# CY8C5888LTI_LP097 register map
File version: 0.1
Registers are 8-bit, read-write, no defined reset value unless marked. A register's access mark holds for its fields unless they carry their own. Offsets are from the block's base; [hi:lo] are bit positions; 'fields as' and 'values as' point back to an identical list.

## MOTOR_ON_OFF_2
Base 0x00000000
0x40006576 MOTOR_ON_OFF_2_CONTROL_REG

## MY_TIMER_REG
Base 0x00000000
0x4000647A MY_TIMER_REG_CONTROL_REG

## MOTOR_DRIVER_TYPE
Base 0x00000000
0x40006472 MOTOR_DRIVER_TYPE_CONTROL_REG

## PACER_RESET
Base 0x00000000
0x40006579 PACER_RESET_CONTROL_REG

## ADC_SOC
Base 0x00000000
0x4000647B ADC_SOC_CONTROL_REG

## ADC_STATUS
Base 0x00000000
0x4000646C ADC_STATUS_STATUS_REG
0x4000648C ADC_STATUS_MASK_REG
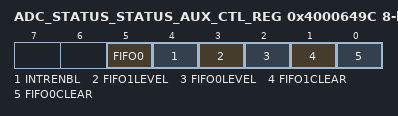
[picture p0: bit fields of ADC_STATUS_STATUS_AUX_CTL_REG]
0x4000649C ADC_STATUS_STATUS_AUX_CTL_REG
  [5] FIFO0 — FIFO0 clear
    1=ENABLED (Enable counter); 0=DISABLED (Disable counter)
  [4] INTRENBL — Enables or disables the Interrupt
    1=ENABLED (Interrupt enabled); 0=DISABLED (Interrupt disabled)
  [3] FIFO1LEVEL — FIFO level
    1=ENABLED (FIFO LVL: input mode: FIFO at least 1/2 empty; output mode: FIFO at least 1/2 full); 0=DISABLED (FIFO LVL: input mode: FIFO not full; output mode: FIFO not empty)
  [2] FIFO0LEVEL — FIFO level
    values as FIFO1LEVEL
  [1] FIFO1CLEAR — FIFO clear
    1=ENABLED (Clear FIFO state); 0=DISABLED (Normal FIFO operation)
  [0] FIFO0CLEAR — FIFO clear
    values as FIFO1CLEAR

## Chip_Select_ENCODER_LINE
Base 0x00000000
0x4000647D Chip_Select_ENCODER_LINE_CONTROL_REG

## RESET_COUNTERS
Base 0x00000000
0x40006475 RESET_COUNTERS_CONTROL_REG

## Chip_Select_IMU
Base 0x00000000
0x4000647F Chip_Select_IMU_CONTROL_REG

## PWM_MOTORS
Base 0x00000000
0x40006428 PWM_MOTORS_COMPARE_1 16-bit — UDB.D0 - Assigned Compare1 Value
0x40006438 PWM_MOTORS_COMPARE_2 16-bit — UDB.D1 - Assigned Compare2 Value
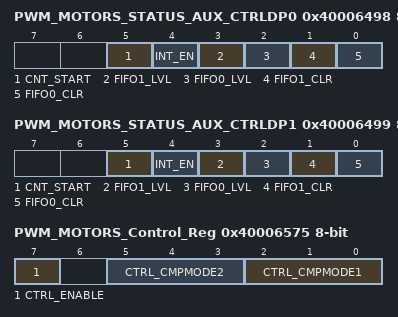
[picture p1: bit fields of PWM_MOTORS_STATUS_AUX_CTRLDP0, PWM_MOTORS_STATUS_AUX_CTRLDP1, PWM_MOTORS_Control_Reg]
0x40006498 PWM_MOTORS_STATUS_AUX_CTRLDP0 — UDB Auxilliary Control Register
  [5] CNT_START — FIFO0 clear
    0=E_CNT_START0 (Disable counter); 1=E_CNT_START1 (Enable counter)
  [4] INT_EN
    0=E_INT_EN0 (Interrupt disabled); 1=E_INT_EN1 (Interrupt enabled)
  [3] FIFO1_LVL — FIFO level
    0=E_FIFO_LVL_0 (FIFO LVL: input mode: FIFO not full; output mode: FIFO not empty); 1=E_FIFO_LVL_1 (FIFO LVL: input mode: FIFO at least 1/2 empty; output mode: FIFO at least 1/2 full)
  [2] FIFO0_LVL — FIFO level
    values as FIFO1_LVL
  [1] FIFO1_CLR — FIFO1 clear
    0=E_FIFO_CLR_0 (Normal FIFO operation); 1=E_FIFO_CLR_1 (Clear FIFO state)
  [0] FIFO0_CLR — FIFO0 clear
    values as FIFO1_CLR
0x40006499 PWM_MOTORS_STATUS_AUX_CTRLDP1 — UDB Auxilliary Control Register
  fields as PWM_MOTORS_STATUS_AUX_CTRLDP0
0x40006575 PWM_MOTORS_Control_Reg — UDB Control Register - Assigned Control Register Value
  [7] CTRL_ENABLE — Enable the PWM
  [5:3] CTRL_CMPMODE2 — Compare mode 2
  [2:0] CTRL_CMPMODE1 — Compare mode 1

## MOTOR_DIR_1
Base 0x00000000
0x4000647C MOTOR_DIR_1_CONTROL_REG

## MOTOR_DIR_2
Base 0x00000000
0x40006577 MOTOR_DIR_2_CONTROL_REG

## FF_STATUS
Base 0x00000000
0x40006461 FF_STATUS_STATUS_REG
0x40006481 FF_STATUS_MASK_REG
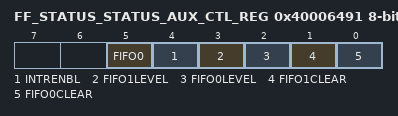
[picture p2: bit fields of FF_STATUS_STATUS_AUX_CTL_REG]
0x40006491 FF_STATUS_STATUS_AUX_CTL_REG
  [5] FIFO0 — FIFO0 clear
    1=ENABLED (Enable counter); 0=DISABLED (Disable counter)
  [4] INTRENBL — Enables or disables the Interrupt
    1=ENABLED (Interrupt enabled); 0=DISABLED (Interrupt disabled)
  [3] FIFO1LEVEL — FIFO level
    1=ENABLED (FIFO LVL: input mode: FIFO at least 1/2 empty; output mode: FIFO at least 1/2 full); 0=DISABLED (FIFO LVL: input mode: FIFO not full; output mode: FIFO not empty)
  [2] FIFO0LEVEL — FIFO level
    values as FIFO1LEVEL
  [1] FIFO1CLEAR — FIFO clear
    1=ENABLED (Clear FIFO state); 0=DISABLED (Normal FIFO operation)
  [0] FIFO0CLEAR — FIFO clear
    values as FIFO1CLEAR

## RESET_FF
Base 0x00000000
0x4000647E RESET_FF_CONTROL_REG
